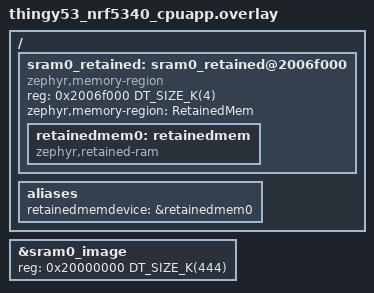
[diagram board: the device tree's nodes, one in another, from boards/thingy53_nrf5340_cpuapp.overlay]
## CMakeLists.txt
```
cmake_minimum_required(VERSION 3.20.0)

find_package(Zephyr REQUIRED HINTS $ENV{ZEPHYR_BASE})
project(fridge_monitor)

target_sources(app PRIVATE
  src/main.cpp
  src/app.cpp
  src/bh1749_light.cpp
)

if(CONFIG_BT)
  target_sources(app PRIVATE
    src/ble_nus.cpp
  )
endif()
```

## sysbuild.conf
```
# Use hci_ipc for BLE on network core instead of empty_net_core.
SB_CONFIG_NETCORE_HCI_IPC=y
```

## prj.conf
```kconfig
# C++
CONFIG_CPP=y
CONFIG_STD_CPP20=y

# I2C for direct BH1749 access (bypassing Zephyr sensor API to avoid SYS_INIT).
CONFIG_I2C=y

# GPIO (for INT)
CONFIG_GPIO=y

# Power management
CONFIG_POWEROFF=y

# nrfx reset reason helper
CONFIG_NRFX_POWER=y

# Retained memory for calibration persistence across System OFF.
CONFIG_RETAINED_MEM=y
CONFIG_CRC=y

# BLE
CONFIG_BT=y
CONFIG_BT_PERIPHERAL=y
CONFIG_BT_DEVICE_NAME="FridgeMon"
CONFIG_BT_NUS=y
# Disable auto connection parameter updates (short-lived connections).
CONFIG_BT_GAP_AUTO_UPDATE_CONN_PARAMS=n

# Logging (RTT)
CONFIG_LOG=y
CONFIG_LOG_DEFAULT_LEVEL=3
CONFIG_USE_SEGGER_RTT=y
CONFIG_LOG_BACKEND_RTT=y
CONFIG_LOG_MODE_IMMEDIATE=y
CONFIG_LOG_BACKEND_UART=n

CONFIG_MAIN_STACK_SIZE=2048
```

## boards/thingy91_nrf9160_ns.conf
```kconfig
# Thingy:91 specific configuration (non-secure build with TF-M).

# Disable TF-M UART logging - it conflicts with I2C (same peripheral base address).
CONFIG_TFM_SECURE_UART=n
CONFIG_TFM_LOG_LEVEL_SILENCE=y

# Thingy:91 uses LTE modem, no BLE.
CONFIG_BT=n
CONFIG_BT_PERIPHERAL=n
CONFIG_BT_NUS=n
```

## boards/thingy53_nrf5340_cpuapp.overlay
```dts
/* BH1749 INT pin is already defined in thingy53_nrf5340_common.dtsi as:
 *   int-gpios = <&gpio1 5 (GPIO_PULL_UP | GPIO_ACTIVE_LOW)>;
 * No overlay needed for that.
 */

/* Retained memory region for calibration persistence across System OFF.
 * Uses the last 4KB of SRAM which remains powered during System OFF.
 */
/ {
  sram0_retained: sram0_retained@2006f000 {
    compatible = "zephyr,memory-region", "mmio-sram";
    reg = <0x2006f000 DT_SIZE_K(4)>;
    zephyr,memory-region = "RetainedMem";
    status = "okay";

    retainedmem0: retainedmem {
      compatible = "zephyr,retained-ram";
      status = "okay";
    };
  };

  aliases {
    retainedmemdevice = &retainedmem0;
  };
};

/* Shrink SRAM to avoid overlap with retained region.
 * Default is 448KB, we reduce to 444KB (448 - 4 = 444).
 */
&sram0_image {
  reg = <0x20000000 DT_SIZE_K(444)>;
};
```

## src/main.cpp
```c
/*
 * Fridge Light Monitor for Thingy:53 (nRF5340)
 *
 * Wakes from System OFF on button press or BH1749 light threshold,
 * monitors door open/close events, transmits data over BLE NUS to gateway,
 * then returns to System OFF.
 */

#include <zephyr/kernel.h>
#include <zephyr/logging/log.h>

#include "app.hpp"

LOG_MODULE_REGISTER(main, LOG_LEVEL_INF);

int main()
{
  LOG_INF("ALC Fridge Light Monitor - Starting.");

  fridge::App app;

  if (!app.Init()) {
    LOG_ERR("Application init failed!");
    return -1;
  }

  app.Run();

  // Run() enters System OFF, so we should never reach here.
  LOG_ERR("Application returned unexpectedly!");
  return -1;
}
```

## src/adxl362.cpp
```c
#include "adxl362.hpp"

#include <zephyr/kernel.h>
#include <zephyr/logging/log.h>

LOG_MODULE_REGISTER(adxl362, LOG_LEVEL_INF);

namespace drawer {

  // ========== SPI Command Bytes ==========

  constexpr uint8_t M_CMD_WRITE_REG  { 0x0A };
  constexpr uint8_t M_CMD_READ_REG   { 0x0B };
  constexpr uint8_t M_CMD_READ_FIFO  { 0x0D };

  // ========== Register Addresses ==========

  constexpr uint8_t M_REG_DEVID_AD        { 0x00 };
  constexpr uint8_t M_REG_DEVID_MST       { 0x01 };
  constexpr uint8_t M_REG_PARTID          { 0x02 };
  constexpr uint8_t M_REG_STATUS          { 0x0B };
  constexpr uint8_t M_REG_FIFO_L          { 0x0C };
  // constexpr uint8_t M_REG_FIFO_H          { 0x0D };
  constexpr uint8_t M_REG_XDATA_L         { 0x0E };
  constexpr uint8_t M_REG_SOFT_RESET      { 0x1F };
  constexpr uint8_t M_REG_THRESH_ACT_L    { 0x20 };
  constexpr uint8_t M_REG_TIME_ACT        { 0x22 };
  constexpr uint8_t M_REG_THRESH_INACT_L  { 0x23 };
  constexpr uint8_t M_REG_TIME_INACT_L    { 0x25 };
  constexpr uint8_t M_REG_ACT_INACT_CTL   { 0x27 };
  constexpr uint8_t M_REG_FIFO_CTL        { 0x28 };
  constexpr uint8_t M_REG_FIFO_SAMPLES    { 0x29 };
  constexpr uint8_t M_REG_INTMAP1         { 0x2A };
  constexpr uint8_t M_REG_FILTER_CTL      { 0x2C };
  constexpr uint8_t M_REG_POWER_CTL       { 0x2D };

  // ========== Bit Masks and Shifts ==========

  // STATUS (0x0B).
  constexpr uint8_t M_STATUS_DATA_READY    { BIT(0) };
  constexpr uint8_t M_STATUS_FIFO_READY    { BIT(1) };
  constexpr uint8_t M_STATUS_FIFO_WM       { BIT(2) };
  constexpr uint8_t M_STATUS_FIFO_OVERRUN  { BIT(3) };
  constexpr uint8_t M_STATUS_ACT           { BIT(4) };
  constexpr uint8_t M_STATUS_INACT         { BIT(5) };
  constexpr uint8_t M_STATUS_AWAKE         { BIT(6) };
  constexpr uint8_t M_STATUS_ERR_USER_REGS { BIT(7) };

  // ACT_INACT_CTL (0x27).
  constexpr uint8_t M_ACT_EN              { BIT(0) };
  // constexpr uint8_t M_ACT_REF             { BIT(1) };
  constexpr uint8_t M_INACT_EN            { BIT(2) };
  // constexpr uint8_t M_INACT_REF           { BIT(3) };
  constexpr uint8_t M_LINKLOOP_SHIFT      { 4 };
  // constexpr uint8_t M_LINKLOOP_MASK       { 0x30 };

  // FIFO_CTL (0x28).
  // constexpr uint8_t M_FIFO_MODE_MASK      { 0x03 };
  // constexpr uint8_t M_FIFO_TEMP           { BIT(2) };
  constexpr uint8_t M_FIFO_AH             { BIT(3) };

  // FILTER_CTL (0x2C).
  constexpr uint8_t M_ODR_MASK            { 0x07 };
  constexpr uint8_t M_RANGE_SHIFT         { 6 };
  constexpr uint8_t M_RANGE_MASK          { 0xC0 };

  // POWER_CTL (0x2D).
  constexpr uint8_t M_MEASURE_MASK        { 0x03 };
  constexpr uint8_t M_MEASURE_ON          { 0x02 };
  constexpr uint8_t M_MEASURE_STANDBY     { 0x00 };
  // constexpr uint8_t M_AUTOSLEEP           { BIT(2) };
  // constexpr uint8_t M_WAKEUP              { BIT(3) };
  // constexpr uint8_t M_LOW_NOISE_SHIFT     { 4 };
  // constexpr uint8_t M_LOW_NOISE_MASK      { 0x30 };
  // constexpr uint8_t M_EXTCLK             { BIT(6) };

  // INTMAP1 (0x2A).
  // constexpr uint8_t M_INTMAP_DATA_READY   { BIT(0) };
  // constexpr uint8_t M_INTMAP_FIFO_READY   { BIT(1) };
  // constexpr uint8_t M_INTMAP_FIFO_WM      { BIT(2) };
  // constexpr uint8_t M_INTMAP_FIFO_OVERRUN { BIT(3) };
  // constexpr uint8_t M_INTMAP_ACT          { BIT(4) };
  // constexpr uint8_t M_INTMAP_INACT        { BIT(5) };
  constexpr uint8_t M_INTMAP_AWAKE        { BIT(6) };
  // constexpr uint8_t M_INTMAP_INT_LOW      { BIT(7) };

  // FIFO data format.
  // constexpr uint16_t M_FIFO_HDR_MASK      { 0xC000 };
  // constexpr uint8_t  M_FIFO_HDR_SHIFT     { 14 };
  constexpr uint16_t M_FIFO_DATA_MASK     { 0x3FFF };
  constexpr uint16_t M_FIFO_SIGN_BIT      { 0x2000 };
  constexpr uint16_t M_FIFO_SIGN_EXTEND   { 0xC000 };

  // Scale factors (mg per LSB).
  constexpr float M_SCALE_2G { 1.0f };     // 1000 LSB/g → 1 mg/LSB.
  constexpr float M_SCALE_4G { 2.0f };     // 500 LSB/g → 2 mg/LSB.
  constexpr float M_SCALE_8G { 4.255f };   // 235 LSB/g → ~4.255 mg/LSB.

  // Threshold scale (mg per LSB, same as data for ±2g default).
  // constexpr float M_THRESH_SCALE_2G { 1.0f };
  // constexpr float M_THRESH_SCALE_4G { 2.0f };
  // constexpr float M_THRESH_SCALE_8G { 4.255f };

  // FIFO entry count mask.
  // constexpr uint16_t M_FIFO_COUNT_MASK { 0x03FF };

  // ========== Constructor ==========

  Adxl362::Adxl362(const struct spi_dt_spec* spiSpec)
      : m_spi(spiSpec)
      , m_currentRange(Range::Range2g)
  {
  }

  // ========== SPI Helpers ==========

  int Adxl362::writeRegister(uint8_t reg, uint8_t value)
  {
    uint8_t txBuf[3] { M_CMD_WRITE_REG, reg, value };
    const struct spi_buf tx { .buf = txBuf, .len = sizeof(txBuf) };
    const struct spi_buf_set txSet { .buffers = &tx, .count = 1 };

    int result { spi_write_dt(m_spi, &txSet) };
    if (result < 0) {
      LOG_ERR("SPI write failed: reg=0x%02X, err=%d!", reg, result);
    }
    return result;
  }

  int Adxl362::readRegister(uint8_t reg, uint8_t& value)
  {
    uint8_t txBuf[2] { M_CMD_READ_REG, reg };
    const struct spi_buf txSpi { .buf = txBuf, .len = sizeof(txBuf) };
    const struct spi_buf_set txSet { .buffers = &txSpi, .count = 1 };

    uint8_t rxBuf[3] { 0 };
    const struct spi_buf rxSpi { .buf = rxBuf, .len = sizeof(rxBuf) };
    const struct spi_buf_set rxSet { .buffers = &rxSpi, .count = 1 };

    int result { spi_transceive_dt(m_spi, &txSet, &rxSet) };
    if (result < 0) {
      LOG_ERR("SPI read failed: reg=0x%02X, err=%d!", reg, result);
      return result;
    }

    // Data appears after 2-byte command in rx buffer.
    value = rxBuf[2];
    return 0;
  }

  int Adxl362::readRegisters(uint8_t reg, uint8_t* buffer, size_t length)
  {
    uint8_t txBuf[2] { M_CMD_READ_REG, reg };
    const struct spi_buf txSpi { .buf = txBuf, .len = sizeof(txBuf) };
    const struct spi_buf_set txSet { .buffers = &txSpi, .count = 1 };

    // RX: 2 dummy bytes (command echo) + data.
    uint8_t rxHeader[2] { 0 };
    struct spi_buf rxBufs[2] {
      { .buf = rxHeader, .len = sizeof(rxHeader) },
      { .buf = buffer,   .len = length },
    };
    const struct spi_buf_set rxSet { .buffers = rxBufs, .count = 2 };

    int result { spi_transceive_dt(m_spi, &txSet, &rxSet) };
    if (result < 0) {
      LOG_ERR("SPI burst read failed: reg=0x%02X, len=%u, err=%d!", reg, length, result);
    }
    return result;
  }

  int Adxl362::writeRegister16(uint8_t regLow, uint16_t value)
  {
    // ADXL362 multi-byte registers are little-endian.
    uint8_t txBuf[4] {
      M_CMD_WRITE_REG,
      regLow,
      static_cast<uint8_t>(value & 0xFF),
      static_cast<uint8_t>((value >> 8) & 0xFF)
    };
    const struct spi_buf tx { .buf = txBuf, .len = sizeof(txBuf) };
    const struct spi_buf_set txSet { .buffers = &tx, .count = 1 };

    int result { spi_write_dt(m_spi, &txSet) };
    if (result < 0) {
      LOG_ERR("SPI write16 failed: reg=0x%02X, err=%d!", regLow, result);
    }
    return result;
  }

  int Adxl362::updateRegister(uint8_t reg, uint8_t value, uint8_t mask)
  {
    uint8_t current { 0 };
    int result { readRegister(reg, current) };
    if (result < 0) { return result; }

    uint8_t updated { static_cast<uint8_t>((current & ~mask) | (value & mask)) };
    return writeRegister(reg, updated);
  }

  int Adxl362::readFifoBurst(uint8_t* buffer, size_t length)
  {
    uint8_t cmd { M_CMD_READ_FIFO };
    const struct spi_buf txSpi { .buf = &cmd, .len = 1 };
    const struct spi_buf_set txSet { .buffers = &txSpi, .count = 1 };

    // RX: 1 dummy byte (command echo) + FIFO data.
    uint8_t rxDummy { 0 };
    struct spi_buf rxBufs[2] {
      { .buf = &rxDummy, .len = 1 },
      { .buf = buffer,   .len = length },
    };
    const struct spi_buf_set rxSet { .buffers = rxBufs, .count = 2 };

    int result { spi_transceive_dt(m_spi, &txSet, &rxSet) };
    if (result < 0) {
      LOG_ERR("FIFO burst read failed: len=%u, err=%d!", length, result);
    }
    return result;
  }

  // ========== Conversion Helpers ==========

  float Adxl362::getScaleMgPerLsb() const
  {
    switch (m_currentRange) {
      case Range::Range2g: return M_SCALE_2G;
      case Range::Range4g: return M_SCALE_4G;
      case Range::Range8g: return M_SCALE_8G;
      default:             return M_SCALE_2G;
    }
  }

  uint16_t Adxl362::mgToLsb(uint16_t mg) const
  {
    float scale { getScaleMgPerLsb() };
    return static_cast<uint16_t>(static_cast<float>(mg) / scale);
  }

  int Adxl362::verifyDeviceId()
  {
    uint8_t adId { 0 };
    uint8_t memsId { 0 };
    uint8_t partId { 0 };

    int result { readRegister(M_REG_DEVID_AD, adId) };
    if (result < 0) { return result; }

    result = readRegister(M_REG_DEVID_MST, memsId);
    if (result < 0) { return result; }

    result = readRegister(M_REG_PARTID, partId);
    if (result < 0) { return result; }

    if (adId != M_DEVID_AD_EXPECTED || memsId != M_DEVID_MST_EXPECTED ||
        partId != M_PARTID_EXPECTED) {
      LOG_ERR("Device ID mismatch: AD=0x%02X MST=0x%02X PART=0x%02X!", adId, memsId, partId);
      return -ENODEV;
    }

    LOG_INF("Device ID verified: AD=0x%02X MST=0x%02X PART=0x%02X.", adId, memsId, partId);
    return 0;
  }

  // ========== Initialisation ==========

  int Adxl362::Init()
  {
    if (!spi_is_ready_dt(m_spi)) {
      LOG_ERR("SPI bus not ready!");
      return -ENODEV;
    }

    // Software reset.
    int result { writeRegister(M_REG_SOFT_RESET, M_SOFT_RESET_CODE) };
    if (result < 0) {
      LOG_ERR("Soft reset failed: %d!", result);
      return result;
    }

    k_msleep(M_RESET_DELAY_MS);

    result = verifyDeviceId();
    if (result < 0) { return result; }

    LOG_INF("ADXL362 initialised.");
    return 0;
  }

  // ========== Configuration ==========

  int Adxl362::ConfigureActivity(const ActivityConfig& config)
  {
    // Activity threshold (11-bit, little-endian across two registers).
    uint16_t actLsb { static_cast<uint16_t>(mgToLsb(config.activityThresholdMg) & 0x07FF) };
    int result { writeRegister16(M_REG_THRESH_ACT_L, actLsb) };
    if (result < 0) { return result; }

    // Activity time.
    result = writeRegister(M_REG_TIME_ACT, config.activityTime);
    if (result < 0) { return result; }

    // Inactivity threshold (11-bit).
    uint16_t inactLsb { static_cast<uint16_t>(mgToLsb(config.inactivityThresholdMg) & 0x07FF) };
    result = writeRegister16(M_REG_THRESH_INACT_L, inactLsb);
    if (result < 0) { return result; }

    // Inactivity time (16-bit).
    result = writeRegister16(M_REG_TIME_INACT_L, config.inactivityTime);
    if (result < 0) { return result; }

    // ACT_INACT_CTL: enable bits, reference mode, link/loop.
    uint8_t ctlValue { static_cast<uint8_t>(
        M_ACT_EN |
        (static_cast<uint8_t>(config.activityMode) << 1) |
        M_INACT_EN |
        (static_cast<uint8_t>(config.inactivityMode) << 3) |
        (static_cast<uint8_t>(config.linkLoop) << M_LINKLOOP_SHIFT)
    )};

    result = writeRegister(M_REG_ACT_INACT_CTL, ctlValue);
    if (result < 0) { return result; }

    LOG_INF("Activity configured: act=%umg/%u, inact=%umg/%u, loop=%u.",
            config.activityThresholdMg, config.activityTime,
            config.inactivityThresholdMg, config.inactivityTime,
            static_cast<uint8_t>(config.linkLoop));
    return 0;
  }

  int Adxl362::ConfigureFifo(FifoMode mode, uint16_t watermark)
  {
    uint8_t fifoCtl { static_cast<uint8_t>(mode) };
    if (watermark & 0x100) {
      fifoCtl |= M_FIFO_AH;
    }

    int result { writeRegister(M_REG_FIFO_CTL, fifoCtl) };
    if (result < 0) { return result; }

    result = writeRegister(M_REG_FIFO_SAMPLES, static_cast<uint8_t>(watermark & 0xFF));
    if (result < 0) { return result; }

    LOG_INF("FIFO configured: mode=%u, watermark=%u.", static_cast<uint8_t>(mode), watermark);
    return 0;
  }

  int Adxl362::SetOdr(ODR odr)
  {
    int result { updateRegister(M_REG_FILTER_CTL, static_cast<uint8_t>(odr), M_ODR_MASK) };
    if (result < 0) {
      LOG_ERR("Failed to set ODR: %d!", result);
      return result;
    }

    LOG_INF("ODR set to %u.", static_cast<uint8_t>(odr));
    return 0;
  }

  int Adxl362::SetRange(Range range)
  {
    uint8_t value { static_cast<uint8_t>(static_cast<uint8_t>(range) << M_RANGE_SHIFT) };
    int result { updateRegister(M_REG_FILTER_CTL, value, M_RANGE_MASK) };
    if (result < 0) {
      LOG_ERR("Failed to set range: %d!", result);
      return result;
    }

    m_currentRange = range;

    const char* rangeStr[] { "±2g", "±4g", "±8g" };
    LOG_INF("Range set to %s.", rangeStr[static_cast<uint8_t>(range)]);
    return 0;
  }

  int Adxl362::StartMeasurement()
  {
    int result { updateRegister(M_REG_POWER_CTL, M_MEASURE_ON, M_MEASURE_MASK) };
    if (result < 0) {
      LOG_ERR("Failed to start measurement: %d!", result);
      return result;
    }

    LOG_INF("Measurement mode started.");
    return 0;
  }

  int Adxl362::StopMeasurement()
  {
    int result { updateRegister(M_REG_POWER_CTL, M_MEASURE_STANDBY, M_MEASURE_MASK) };
    if (result < 0) {
      LOG_ERR("Failed to stop measurement: %d!", result);
      return result;
    }

    LOG_INF("Standby mode entered.");
    return 0;
  }

  // ========== FIFO ==========

  int Adxl362::ReadFifoEntries(uint16_t& entries)
  {
    uint8_t buf[2] { 0 };
    int result { readRegisters(M_REG_FIFO_L, buf, 2) };
    if (result < 0) { return result; }

    entries = static_cast<uint16_t>(buf[0] | ((buf[1] & 0x03) << 8));
    return 0;
  }

  int Adxl362::ReadFifo(Sample* samples, uint16_t maxSets, uint16_t& setsRead)
  {
    constexpr int OK { 0 };
    constexpr size_t TOTAL_AXES { 3 };
    constexpr size_t BYTES_PER_AXIS { 2 } ;
    constexpr size_t TOTAL_SETS { 512 };
    constexpr size_t BYTES_PER_SET { TOTAL_AXES * BYTES_PER_AXIS };

    setsRead = 0;

    // Read FIFO entry count.
    uint16_t entries { 0 };
    int result { ReadFifoEntries(entries) };
    if (result < 0) { return result; }

    LOG_INF("FIFO entries: %u.", entries);
    if (entries == 0) { return 0; }

    // Each XYZ set = 3 entries of 2 bytes each.
    uint16_t availableSets { static_cast<uint16_t>(entries / TOTAL_AXES) };
    uint16_t setsToRead { (availableSets > maxSets) ? maxSets : availableSets };
    uint16_t bytesToRead { static_cast<uint16_t>(setsToRead * BYTES_PER_SET) };

    if (bytesToRead == 0) { return 0; }

    // Read raw FIFO data.
    uint8_t raw[TOTAL_SETS * BYTES_PER_SET];  // 3072.
    if (bytesToRead > sizeof(raw)) {
      setsToRead = sizeof(raw) / BYTES_PER_SET;
      bytesToRead = static_cast<uint16_t>(setsToRead * BYTES_PER_SET);
    }

    result = readFifoBurst(raw, bytesToRead);
    if (result < 0) {
      LOG_ERR("FIFO burst read failed: %d!", result);
      return result;
    }

    // Decode samples from FIFO format.
    // Each entry: bits[15:14] = channel ID, bits[13:0] = signed 14-bit data.
    float scale { getScaleMgPerLsb() };

    for (uint16_t i { 0 }; i < setsToRead; ++i) 
    {
      for (uint8_t axis { 0 }; axis < TOTAL_AXES; ++axis) 
      {
        uint16_t offset { static_cast<uint16_t>((i * TOTAL_AXES + axis) * BYTES_PER_AXIS) };
        uint16_t raw16 { static_cast<uint16_t>(raw[offset] | (raw[offset + 1] << 8)) };

        // Extract 14-bit signed value.
        int16_t rawVal { static_cast<int16_t>(raw16 & M_FIFO_DATA_MASK) };
        if (rawVal & M_FIFO_SIGN_BIT) {
          rawVal |= static_cast<int16_t>(M_FIFO_SIGN_EXTEND);
        }

        int16_t mg { static_cast<int16_t>(static_cast<float>(rawVal) * scale) };

        switch (axis) {
          case 0: samples[i].x = mg; break;
          case 1: samples[i].y = mg; break;
          case 2: samples[i].z = mg; break;
        }
      }
    }

    setsRead = setsToRead;
    LOG_INF("Read %u sample sets from FIFO.", setsRead);

    return OK;
  }

  // ========== Status ==========

  int Adxl362::ReadStatus(Status& status)
  {
    constexpr int OK { 0 };
    uint8_t value { 0 };
    int result { readRegister(M_REG_STATUS, value) };
    if (result < 0) {
      LOG_ERR("Failed to read status: %d!", result);
      return result;
    }

    status.dataReady     = (value & M_STATUS_DATA_READY) != 0;
    status.fifoReady     = (value & M_STATUS_FIFO_READY) != 0;
    status.fifoWatermark = (value & M_STATUS_FIFO_WM) != 0;
    status.fifoOverrun   = (value & M_STATUS_FIFO_OVERRUN) != 0;
    status.activity      = (value & M_STATUS_ACT) != 0;
    status.inactivity    = (value & M_STATUS_INACT) != 0;
    status.awake         = (value & M_STATUS_AWAKE) != 0;
    status.errUserRegs   = (value & M_STATUS_ERR_USER_REGS) != 0;

    return OK;
  }

  bool Adxl362::IsAwake()
  {
    Status status;
    if (ReadStatus(status) < 0) {
      return true;  // Default to awake on error (safer).
    }
    return status.awake;
  }

  // ========== Interrupt Mapping ==========

  int Adxl362::MapAwakeToInt1()
  {
    constexpr int OK { 0 };
    int result { writeRegister(M_REG_INTMAP1, M_INTMAP_AWAKE) };
    if (result < 0) {
      LOG_ERR("Failed to map AWAKE to INT1: %d!", result);
      return result;
    }

    LOG_INF("AWAKE mapped to INT1.");

    return OK;
  }

  // ========== Data Register Reads ==========

  int Adxl362::ReadAxes(int16_t& x, int16_t& y, int16_t& z)
  {
    constexpr int OK { 0 };
    // Burst read 6 bytes: XDATA_L, XDATA_H, YDATA_L, YDATA_H, ZDATA_L, ZDATA_H.
    uint8_t raw[6];
    int result { readRegisters(M_REG_XDATA_L, raw, 6) };
    if (result < 0) {
      LOG_ERR("Failed to read axes: %d!", result);
      return result;
    }

    float scale { getScaleMgPerLsb() };

    // Data registers are 12-bit, little-endian, right-justified.
    auto decode = [scale](uint8_t lo, uint8_t hi) -> int16_t {
      int16_t rawVal { static_cast<int16_t>((hi << 8) | lo) };
      return static_cast<int16_t>(static_cast<float>(rawVal) * scale);
    };

    x = decode(raw[0], raw[1]);
    y = decode(raw[2], raw[3]);
    z = decode(raw[4], raw[5]);

    return OK;
  }
}
```

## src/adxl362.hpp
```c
#pragma once

/**
 * @file adxl362.hpp
 * @brief ADXL362 accelerometer driver — Zephyr-free class using direct SPI register access.
 *
 * Provides activity/inactivity detection (loop mode), FIFO streaming, and AWAKE→INT1
 * mapping for System OFF wake. Uses SPI via Zephyr's spi_dt_spec only for bus access;
 * all register configuration is handled directly (no Zephyr sensor API at runtime).
 */

#include <zephyr/device.h>
#include <zephyr/drivers/spi.h>

namespace drawer 
{
  class Adxl362
  {
    public:
      // ========== Enumerations ==========

      enum class Range : uint8_t {
        Range2g = 0x00,   ///< ±2g (1000 LSB/g).
        Range4g = 0x01,   ///< ±4g (500 LSB/g).
        Range8g = 0x02    ///< ±8g (235 LSB/g).
      };

      enum class ODR : uint8_t {
        Odr12_5  = 0x00,  ///< 12.5 Hz.
        Odr25    = 0x01,  ///< 25 Hz.
        Odr50    = 0x02,  ///< 50 Hz.
        Odr100   = 0x03,  ///< 100 Hz.
        Odr200   = 0x04,  ///< 200 Hz.
        Odr400   = 0x05   ///< 400 Hz.
      };

      enum class FifoMode : uint8_t {
        Disabled     = 0x00,
        OldestSaved  = 0x01,
        Stream       = 0x02,
        Triggered    = 0x03
      };

      enum class LinkLoopMode : uint8_t {
        Default = 0x00,   ///< Default (independent act/inact).
        Linked  = 0x01,   ///< Linked mode.
        Loop    = 0x03    ///< Loop mode (auto-acknowledged).
      };

      enum class ActivityMode : uint8_t {
        Absolute   = 0x00,
        Referenced = 0x01
      };

      // ========== Structures ==========

      /** @brief Decoded status register contents. */
      struct Status {
        bool dataReady;       ///< New data available.
        bool fifoReady;       ///< FIFO has at least one sample.
        bool fifoWatermark;   ///< FIFO watermark reached.
        bool fifoOverrun;     ///< FIFO overrun.
        bool activity;        ///< Activity detected.
        bool inactivity;      ///< Inactivity detected.
        bool awake;           ///< Device is in awake state.
        bool errUserRegs;     ///< SEU error detected in user registers.
      };

      /** @brief Single XYZ acceleration sample in mg. */
      struct Sample {
        int16_t x;
        int16_t y;
        int16_t z;
      };

      /** @brief Activity/inactivity detection configuration. */
      struct ActivityConfig {
        ActivityMode activityMode;
        ActivityMode inactivityMode;
        LinkLoopMode linkLoop;
        uint16_t activityThresholdMg;     ///< Activity threshold in mg.
        uint8_t  activityTime;            ///< Activity time in samples.
        uint16_t inactivityThresholdMg;   ///< Inactivity threshold in mg.
        uint16_t inactivityTime;          ///< Inactivity time in samples.
      };

      /** @brief Default config for drawer motion detection. */
      static constexpr ActivityConfig DEFAULT_DRAWER_CONFIG {
        .activityMode         = ActivityMode::Referenced,
        .inactivityMode       = ActivityMode::Referenced,
        .linkLoop             = LinkLoopMode::Loop,
        .activityThresholdMg  = 120,
        .activityTime         = 1,
        .inactivityThresholdMg = 150,
        .inactivityTime       = 200    // 2s at 100 Hz.
      };

      // ========== Constructor ==========

      /**
       * @brief Construct an ADXL362 driver instance.
       * @param spiSpec Pointer to a Zephyr spi_dt_spec (from devicetree).
       */
      explicit Adxl362(const struct spi_dt_spec* spiSpec);

      // ========== Initialisation ==========

      /** @brief Reset device, verify ID, and apply default configuration. */
      int Init();

      // ========== Configuration ==========

      /** @brief Configure activity/inactivity detection and link/loop mode. */
      int ConfigureActivity(const ActivityConfig& config);

      /** @brief Configure FIFO mode and watermark. */
      int ConfigureFifo(FifoMode mode, uint16_t watermark);

      /** @brief Set output data rate. */
      int SetOdr(ODR odr);

      /** @brief Set measurement range. */
      int SetRange(Range range);

      /** @brief Enter measurement mode. */
      int StartMeasurement();

      /** @brief Return to standby. */
      int StopMeasurement();

      // ========== FIFO ==========

      /** @brief Read FIFO entry count (number of 16-bit words). */
      int ReadFifoEntries(uint16_t& entries);

      /**
       * @brief Read complete XYZ sample sets from FIFO.
       * @param samples Output buffer for decoded samples.
       * @param maxSets Maximum number of XYZ sets to read.
       * @param setsRead Actual number of sets read.
       */
      int ReadFifo(Sample* samples, uint16_t maxSets, uint16_t& setsRead);

      // ========== Status ==========

      /** @brief Read and decode the status register. */
      int ReadStatus(Status& status);

      /** @brief Check if device is in awake state. */
      bool IsAwake();

      // ========== Interrupt Mapping ==========

      /** @brief Map AWAKE signal to INT1 for System OFF wake. */
      int MapAwakeToInt1();

      // ========== Data Register Reads ==========

      /** @brief Read XYZ from data registers (not FIFO). */
      int ReadAxes(int16_t& x, int16_t& y, int16_t& z);

    private:
      // ========== SPI Helpers ==========

      int writeRegister(uint8_t reg, uint8_t value);
      int readRegister(uint8_t reg, uint8_t& value);
      int readRegisters(uint8_t reg, uint8_t* buffer, size_t length);
      int writeRegister16(uint8_t regLow, uint16_t value);
      int updateRegister(uint8_t reg, uint8_t value, uint8_t mask);
      int readFifoBurst(uint8_t* buffer, size_t length);

      // ========== Conversion Helpers ==========

      uint16_t mgToLsb(uint16_t mg) const;
      float getScaleMgPerLsb() const;
      int verifyDeviceId();

      // ========== Member Variables ==========

      const struct spi_dt_spec* m_spi;
      Range m_currentRange;

      // ========== Constants ==========

      static constexpr uint8_t M_RESET_DELAY_MS    { 5 };
      static constexpr uint8_t M_SOFT_RESET_CODE   { 0x52 };
      static constexpr uint8_t M_DEVID_AD_EXPECTED  { 0xAD };
      static constexpr uint8_t M_DEVID_MST_EXPECTED { 0x1D };
      static constexpr uint8_t M_PARTID_EXPECTED    { 0xF2 };
  };
} 
```

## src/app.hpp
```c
#pragma once

/**
 * @file app.hpp
 * @brief ALC Fridge Light Monitor Application State Machine.
 *
 * Manages the device lifecycle from activation through normal operation:
 *
 * States:
 * - PowerOff:    Deep sleep (System OFF), waiting for button or light wake.
 * - Activating:  User pressed button, searching for gateway, calibrating.
 * - NoCentral:   Gateway not found during activation.
 * - Standby:     Activation failed or uncalibrated, waiting for button retry.
 * - Ready:       Activated and calibrated, waiting for light wake.
 * - Monitoring:  Light detected (door open), monitoring for close.
 *
 * Button (sw0 / SW2 on Thingy:53 silkscreen, P1.14):
 * - Short press from PowerOff/Standby: Start activation.
 * - Long press (3s) from any state: Power off.
 * - Very long press (10s): Factory reset (clear calibration).
 *
 * Light sensor (BH1749 INT on P1.05):
 * - Wake from System OFF when light exceeds calibrated threshold.
 * - Send OPEN event, monitor for door close, send CLOSE event with duration.
 * - Alert if door open > timeout.
 */

#include <cstdint>

namespace fridge
{
  // ========== Application States ==========

  enum class AppState : uint8_t {
    PowerOff,       // System OFF, waiting for wake.
    Activating,     // Button pressed, finding gateway + calibrating.
    NoCentral,      // Gateway not found.
    Standby,        // Failed activation, waiting for retry.
    Ready,          // Activated, waiting for light wake.
    Monitoring      // Door open, monitoring for close.
  };

  // ========== Wake Source Identification ==========

  enum class WakeSource : uint8_t {
    PowerOn,        // Fresh boot (power-on reset, debug reset, etc.).
    Button,         // User pressed button (sw0).
    LightInterrupt  // BH1749 light threshold exceeded (door opened).
  };

  // ========== Calibration Data ==========

  struct CalibrationData {
    uint16_t wakeThreshold;     // Light level to trigger wake (green channel).
    uint16_t doorOpenLight;     // Measured door-open light level (green channel).
    uint16_t doorClosedLight;   // Measured door-closed light level (green channel).
    int8_t txPowerDbm;          // Calibrated TX power.
    uint8_t valid;              // Magic number to detect uninitialised.
  };

  // Magic value indicating valid calibration.
  constexpr uint8_t M_CALIBRATION_VALID_MAGIC { 0xCA };

  // ========== Timing Constants ==========

  constexpr uint32_t M_BUTTON_LONG_PRESS_MS { 3000 };      // Power off threshold.
  constexpr uint32_t M_BUTTON_FACTORY_RESET_MS { 10000 };  // Factory reset threshold.
  constexpr uint32_t M_ACTIVATION_TIMEOUT_MS { 30000 };    // Gateway search timeout.
  constexpr uint32_t M_CALIBRATION_TIMEOUT_MS { 300000 };  // 5 minutes for door close.
  constexpr uint32_t M_POLL_INTERVAL_MS { 500 };           // Calibration poll interval.

  // ========== Calibration Constants ==========

  constexpr uint8_t M_SAMPLES_PER_READING { 5 };           // Samples averaged per reading.
  constexpr uint8_t M_DOOR_CLOSE_CONSECUTIVE { 3 };        // Consecutive low readings to confirm closed.
  constexpr uint8_t M_DOOR_CLOSE_THRESHOLD_PERCENT { 30 }; // % of open level to detect closed.
  constexpr uint8_t M_VALID_CALIBRATION_PERCENT { 50 };    // Max closed/open ratio for valid cal.
  constexpr uint8_t M_WAKE_THRESHOLD_OFFSET_PERCENT { 30 };// Wake threshold: closed + 30% of range.

  // ========== Application Class ==========

  class App
  {
    public:
      App();

      /**
       * @brief Initialise application hardware.
       * @return true on success.
       */
      bool Init();

      /**
       * @brief Run the application state machine.
       *
       * Handles the current wake event and transitions to appropriate state.
       * May enter System OFF at the end.
       */
      void Run();

      /**
       * @brief Get the wake source that caused this boot.
       * @return The detected wake source.
       */
      WakeSource GetWakeSource() const { return m_wakeSource; }

      /**
       * @brief Get the current application state.
       * @return The current state.
       */
      AppState GetState() const { return m_state; }

    private:
      // ========== State Handlers ==========

      void handlePowerOnWake();
      void handleButtonWake();
      void handleLightInterruptWake();

      // ========== Button Handling ==========

      bool checkFactoryReset();

      // ========== Activation Sequence ==========

      bool runActivationSequence();
      bool findGateway();
      bool calibrateLightSensor();

      // ========== Normal Operation ==========

      void sendDoorOpenAndSleep();
      bool sendOpenEvent(int8_t rssi, int8_t txPower);

      // ========== Calibration Events ==========

      bool sendCalibrationEvent(uint8_t status, int8_t rssi);

      // ========== Hardware Configuration ==========

      bool initLightSensor();
      void configureLightSensorForWake();
      void configureLightSensorForDoorClose();

      // ========== Wake Source Detection ==========

      WakeSource detectWakeSource();

      // ========== LED Feedback ==========

      void ledSetAmber();
      void ledSetRed();
      void ledSetGreen();
      void ledOff();
      void ledBlink(int count, int onMs, int offMs);
      void ledPulseAmber();
      void ledStopPulse();

      // ========== Power Management ==========

      void configureWakeSources();
      void enterSystemOff();

      // ========== State Management ==========

      void setState(AppState newState);

      // ========== Calibration Persistence ==========

      bool loadCalibration();
      void saveCalibration();
      void saveRetainedData();
      void clearCalibration();
      bool isCalibrated() const;

      // ========== Helper Functions ==========

      uint16_t calculateWakeThreshold(uint16_t doorOpenLight, uint16_t doorClosedLight);
      uint16_t sampleLightLevel();  // Takes M_SAMPLES_PER_READING samples and averages.

      // ========== Member Variables ==========

      AppState m_state;
      WakeSource m_wakeSource;
      CalibrationData m_calibration;
      uint16_t m_doorOpenLight;      // Light level when door opened (this wake cycle).
  };

  // ========== Free Functions ==========

  const char* appStateToString(AppState state);
  const char* wakeSourceToString(WakeSource source);

} // namespace fridge
```

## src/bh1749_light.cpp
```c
#include <zephyr/kernel.h>
#include <zephyr/drivers/i2c.h>
#include <zephyr/logging/log.h>

#include "bh1749_light.hpp"

LOG_MODULE_REGISTER(bh1749_light, LOG_LEVEL_INF);

namespace fridge 
{
  // ========== Register Addresses ==========

  constexpr uint8_t M_REG_SYSTEM_CONTROL   { 0x40 };
  constexpr uint8_t M_REG_MODE_CONTROL1    { 0x41 };
  constexpr uint8_t M_REG_MODE_CONTROL2    { 0x42 };
  constexpr uint8_t M_REG_RED_DATA_LSB     { 0x50 };
  constexpr uint8_t M_REG_MANUFACTURER_ID  { 0x92 };

  // Interrupt registers.
  constexpr uint8_t M_REG_INTERRUPT        { 0x60 };
  constexpr uint8_t M_REG_PERSISTENCE      { 0x61 };
  constexpr uint8_t M_REG_TH_HIGH_LSB      { 0x62 };
  constexpr uint8_t M_REG_TH_HIGH_MSB      { 0x63 };
  constexpr uint8_t M_REG_TH_LOW_LSB       { 0x64 };
  constexpr uint8_t M_REG_TH_LOW_MSB       { 0x65 };

  // ========== Register Values ==========

  // SYSTEM_CONTROL.
  constexpr uint8_t M_PART_ID_MASK    { 0x3F };
  constexpr uint8_t M_PART_ID         { 0x0D };
  constexpr uint8_t M_SW_RESET        { 0x80 };

  // MODE_CONTROL1.
  constexpr uint8_t M_MEAS_MODE_35MS  { 0x05 };
  constexpr uint8_t M_MEAS_MODE_120MS { 0x02 };
  constexpr uint8_t M_RGB_GAIN_1X     { 0x01 << 3 };
  constexpr uint8_t M_RGB_GAIN_32X    { 0x03 << 3 };
  constexpr uint8_t M_IR_GAIN_1X      { 0x01 << 5 };
  constexpr uint8_t M_IR_GAIN_32X     { 0x03 << 5 };

  // MODE_CONTROL2.
  constexpr uint8_t M_RGB_EN          { 0x10 };
  constexpr uint8_t M_VALID_MASK      { 0x80 };

  // INTERRUPT register bits.
  constexpr uint8_t M_INT_ENABLE       { 0x01 };
  constexpr uint8_t M_INT_SOURCE_RED   { 0x00 << 2 };  // Red channel as interrupt source.
  constexpr uint8_t M_INT_SOURCE_GREEN { 0x01 << 2 };  // Green channel as interrupt source.
  constexpr uint8_t M_INT_SOURCE_BLUE  { 0x02 << 2 };  // Blue channel as interrupt source.
  constexpr uint8_t M_INT_LATCH_YES    { 0x00 << 4 };  // Latched interrupt mode.
  constexpr uint8_t M_INT_LATCH_NO     { 0x01 << 4 };  // Non-latched interrupt mode.

  // PERSISTENCE register values.
  constexpr uint8_t M_PERSISTENCE_ACTIVE_END { 0x00 };  // After each measurement.
  constexpr uint8_t M_PERSISTENCE_UPDATE_END { 0x01 };  // Update measurement end.
  constexpr uint8_t M_PERSISTENCE_4_SAMPLES  { 0x02 };  // 4 consecutive samples.
  constexpr uint8_t M_PERSISTENCE_8_SAMPLES  { 0x03 };  // 8 consecutive samples.

  // MANUFACTURER_ID.
  constexpr uint8_t M_MANUFACTURER_ID { 0xE0 };

  // ========== Constructor ==========

  Bh1749Light::Bh1749Light(const struct i2c_dt_spec* i2cSpec)
      : m_i2c(i2cSpec)
  {
  }

  // ========== Private Methods ==========

  int Bh1749Light::readRegister(uint8_t reg, uint8_t& value)
  {
    return i2c_reg_read_byte_dt(m_i2c, reg, &value);
  }

  int Bh1749Light::writeRegister(uint8_t reg, uint8_t value)
  {
    return i2c_reg_write_byte_dt(m_i2c, reg, value);
  }

  int Bh1749Light::readRegisters(uint8_t startReg, uint8_t* buffer, size_t length)
  {
    return i2c_burst_read_dt(m_i2c, startReg, buffer, length);
  }

  int Bh1749Light::writeRegisters(uint8_t startReg, const uint8_t* buffer, size_t length)
  {
    return i2c_burst_write_dt(m_i2c, startReg, buffer, length);
  }

  // ========== Public Methods ==========

  int Bh1749Light::Init()
  {
    if (!device_is_ready(m_i2c->bus)) {
      LOG_ERR("I2C bus not ready!");
      return -ENODEV;
    }

    // Software reset to ensure clean state.
    int result { writeRegister(M_REG_SYSTEM_CONTROL, M_SW_RESET) };
    if (result < 0) {
      LOG_ERR("Failed to reset BH1749: %d!", result);
      return result;
    }

    // Wait for reset to complete.
    k_msleep(10);

    // Verify manufacturer ID.
    uint8_t mfgId;
    result = readRegister(M_REG_MANUFACTURER_ID, mfgId);
    if (result < 0) {
      LOG_ERR("Failed to read manufacturer ID: %d!", result);
      return result;
    }

    if (mfgId != M_MANUFACTURER_ID) {
      LOG_ERR("Wrong manufacturer ID: 0x%02X (expected 0x%02X)!", mfgId, M_MANUFACTURER_ID);
      return -ENODEV;
    }

    // Verify part ID.
    uint8_t sysCtrl { };
    result = readRegister(M_REG_SYSTEM_CONTROL, sysCtrl);
    if (result < 0) {
      LOG_ERR("Failed to read system control: %d!", result);
      return result;
    }

    uint8_t partId { static_cast<uint8_t>(sysCtrl & M_PART_ID_MASK) };
    if (partId != M_PART_ID) {
      LOG_ERR("Wrong part ID: 0x%02X (expected 0x%02X)!", partId, M_PART_ID);
      return -ENODEV;
    }

    // Set configuration: 32x gain, 120ms mode.
    // Must write MODE_CONTROL1 before enabling measurement in MODE_CONTROL2.
    // 0x02 = 120ms, 0x18 = RGB 32x (bits 4:3 = 11), 0x60 = IR 32x (bits 6:5 = 11)
    constexpr uint8_t MODE_CONTROL1_32X { 0x02 | 0x18 | 0x60 };  // = 0x7A
    result = writeRegister(M_REG_MODE_CONTROL1, MODE_CONTROL1_32X);
    if (result < 0) {
      LOG_ERR("Failed to set mode control 1: %d!", result);
      return result;
    }

    // Enable RGB measurement after setting gain/timing.
    result = writeRegister(M_REG_MODE_CONTROL2, M_RGB_EN);
    if (result < 0) {
      LOG_ERR("Failed to enable RGB: %d!", result);
      return result;
    }

    // Verify gain was set correctly.
    uint8_t modeCtrl1Readback;
    result = readRegister(M_REG_MODE_CONTROL1, modeCtrl1Readback);
    if (result == 0) {
      LOG_INF("MODE_CONTROL1: 0x%02X (expected 0x7A).", modeCtrl1Readback);
    }

    // Clear any pending interrupt from power-on.
    // The BH1749 thresholds default to 0x0000, so any measured value will trigger
    // the interrupt immediately. Reading register 0x60 clears the latch.
    uint8_t intStatus;
    result = readRegister(M_REG_INTERRUPT, intStatus);
    if (result < 0) {
      LOG_WRN("Failed to read/clear interrupt register: %d.", result);
      // Non-fatal, continue.
    } else {
      LOG_INF("Initial INT register: 0x%02X (cleared by reading).", intStatus);
    }

    // Set safe default thresholds to prevent immediate interrupt assertion.
    // High threshold = 0xFFFF (max), Low threshold = 0x0000 (min).
    // This means: interrupt only if value > 65535 (impossible) or < 0 (impossible).
    uint8_t safeThresholds[4] {
      0xFF, 0xFF,  // High threshold LSB, MSB = 0xFFFF.
      0x00, 0x00   // Low threshold LSB, MSB = 0x0000.
    };
    result = writeRegisters(M_REG_TH_HIGH_LSB, safeThresholds, 4);
    if (result < 0) {
      LOG_WRN("Failed to set safe thresholds: %d.", result);
      // Non-fatal, continue.
    } else {
      LOG_INF("Safe thresholds set (high=0xFFFF, low=0x0000).");
    }

    m_ready = true;
    LOG_INF("BH1749 initialised (mfg=0x%02X, part=0x%02X).", mfgId, partId);
    return 0;
  }

  int Bh1749Light::SetGain(Bh1749Gain rgbGain, Bh1749Gain irGain)
  {
    if (!m_ready) { return -ENODEV; }

    uint8_t regVal { M_MEAS_MODE_120MS };
    regVal |= (rgbGain == Bh1749Gain::Gain32x) ? M_RGB_GAIN_32X : M_RGB_GAIN_1X;
    regVal |= (irGain == Bh1749Gain::Gain32x) ? M_IR_GAIN_32X : M_IR_GAIN_1X;

    int result { writeRegister(M_REG_MODE_CONTROL1, regVal) };
    if (result < 0) {
      LOG_ERR("Failed to set gain: %d!", result);
      return result;
    }

    // Clear any stale VALID flag by reading the data registers.
    // This ensures the next Read() waits for fresh data.
    uint8_t dummy[10];
    readRegisters(M_REG_RED_DATA_LSB, dummy, sizeof(dummy));

    LOG_INF("BH1749 gain set: RGB=%s, IR=%s.",
            (rgbGain == Bh1749Gain::Gain32x) ? "32x" : "1x",
            (irGain == Bh1749Gain::Gain32x) ? "32x" : "1x");

    return 0;
  }

  int Bh1749Light::Read(LightReading& reading)
  {
    constexpr int OK { 0 };

    if (!m_ready) { return -ENODEV; }

    // Read all color data (R, G, B, skip 2 bytes, IR) = 10 bytes from 0x50.
    // Layout: RED_L, RED_H, GREEN_L, GREEN_H, BLUE_L, BLUE_H, (2 reserved), IR_L, IR_H.
    // Note: Caller should use WaitForValid() before calling this if fresh data is needed.
    uint8_t buffer[10] { };
    int result { readRegisters(M_REG_RED_DATA_LSB, buffer, sizeof(buffer)) };
    if (result < 0) {
      LOG_ERR("Failed to read color data: %d!", result);
      return result;
    }

    reading.red   = static_cast<uint16_t>(buffer[0] | (buffer[1] << 8));
    reading.green = static_cast<uint16_t>(buffer[2] | (buffer[3] << 8));
    reading.blue  = static_cast<uint16_t>(buffer[4] | (buffer[5] << 8));
    reading.ir    = static_cast<uint16_t>(buffer[8] | (buffer[9] << 8));

    // Store green for threshold checks.
    m_lastGreen = reading.green;

    return OK;
  }

  int Bh1749Light::ConfigureInterrupt(uint16_t thresholdHigh, uint16_t thresholdLow)
  {
    constexpr int OK { 0 };

    if (!m_ready) { return -ENODEV; }

    // Write high threshold (little-endian).
    uint8_t thHighBuf[2] {
      static_cast<uint8_t>(thresholdHigh & 0xFF),
      static_cast<uint8_t>((thresholdHigh >> 8) & 0xFF)
    };
    int result { writeRegisters(M_REG_TH_HIGH_LSB, thHighBuf, 2) };
    if (result < 0) {
      LOG_ERR("Failed to set high threshold: %d!", result);
      return result;
    }

    // Write low threshold (little-endian).
    uint8_t thLowBuf[2] {
      static_cast<uint8_t>(thresholdLow & 0xFF),
      static_cast<uint8_t>((thresholdLow >> 8) & 0xFF)
    };
    result = writeRegisters(M_REG_TH_LOW_LSB, thLowBuf, 2);
    if (result < 0) {
      LOG_ERR("Failed to set low threshold: %d!", result);
      return result;
    }

    // Set persistence to 4 consecutive samples to filter transient changes.
    result = writeRegister(M_REG_PERSISTENCE, M_PERSISTENCE_4_SAMPLES);
    if (result < 0) {
      LOG_ERR("Failed to set persistence: %d!", result);
      return result;
    }

    // Read back to verify.
    constexpr size_t VERIFY_LENGTH { 4 };
    uint8_t verifyBuffer[VERIFY_LENGTH];
    readRegisters(M_REG_TH_HIGH_LSB, verifyBuffer, VERIFY_LENGTH);
    uint16_t readHigh { static_cast<uint16_t>(verifyBuffer[0] | (verifyBuffer[1] << 8)) };
    uint16_t readLow { static_cast<uint16_t>(verifyBuffer[2] | (verifyBuffer[3] << 8)) };

    LOG_INF("BH1749 thresholds: high=%u (read=%u), low=%u (read=%u), persist=4.",
            thresholdHigh, readHigh, thresholdLow, readLow);

    return OK;
  }

  int Bh1749Light::EnableInterrupt(bool enable)
  {
    constexpr int OK { 0 };

    if (!m_ready) { return -ENODEV; }

    // Configure interrupt: green channel source, latched mode.
    // Latched mode keeps INT asserted until cleared by reading register 0x60.
    uint8_t intVal { 0 };
    if (enable) {
      intVal = M_INT_ENABLE | M_INT_SOURCE_GREEN | M_INT_LATCH_YES;
    }

    int result { writeRegister(M_REG_INTERRUPT, intVal) };
    if (result < 0) {
      LOG_ERR("Failed to %s interrupt: %d!", enable ? "enable" : "disable", result);
      return result;
    }

    LOG_INF("BH1749 interrupt %s.", enable ? "enabled" : "disabled");

    return OK;
  }

  int Bh1749Light::ClearInterrupt()
  {
    constexpr int OK { 0 };

    if (!m_ready) { return -ENODEV; }

    // Clear interrupt by READING register 0x60 (INTERRUPT).
    uint8_t intStatus;
    int result { readRegister(M_REG_INTERRUPT, intStatus) };
    if (result < 0) {
      LOG_ERR("Failed to clear interrupt: %d!", result);
      return result;
    }

    LOG_INF("BH1749 interrupt cleared (reg 0x60 was 0x%02X).", intStatus);

    return OK;
  }

  bool Bh1749Light::IsLightAboveThreshold(uint16_t threshold)
  {
    return m_lastGreen >= threshold;
  }

  int Bh1749Light::DumpInterruptRegisters()
  {
    constexpr int OK { 0 };

    if (!m_ready) { return -ENODEV; }

    // Read INTERRUPT register (0x60).
    uint8_t intReg;
    int result { readRegister(M_REG_INTERRUPT, intReg) };
    if (result < 0) {
      LOG_ERR("Failed to read INTERRUPT (0x60): %d!", result);
      return result;
    }

    // Read PERSISTENCE register (0x61).
    uint8_t persReg;
    result = readRegister(M_REG_PERSISTENCE, persReg);
    if (result < 0) {
      LOG_ERR("Failed to read PERSISTENCE (0x61): %d!", result);
      return result;
    }

    // Read threshold registers (0x62-0x65).
    uint8_t threshBuf[4];
    result = readRegisters(M_REG_TH_HIGH_LSB, threshBuf, 4);
    if (result < 0) {
      LOG_ERR("Failed to read thresholds: %d!", result);
      return result;
    }

    uint16_t thHigh { static_cast<uint16_t>(threshBuf[0] | (threshBuf[1] << 8)) };
    uint16_t thLow { static_cast<uint16_t>(threshBuf[2] | (threshBuf[3] << 8)) };

    LOG_INF("BH1749 INT regs: INT=0x%02X, PERS=0x%02X, TH_H=%u, TH_L=%u",
            intReg, persReg, thHigh, thLow);

    // Decode INTERRUPT register bits.
    bool intEn { (intReg & M_INT_ENABLE) != 0 };
    uint8_t intSrc { static_cast<uint8_t>((intReg >> 2) & 0x03) };
    bool latch { (intReg & M_INT_LATCH_NO) == 0 };  // 0 = latched, 1 = non-latched.

    const char* srcNames[] = { "RED", "GREEN", "BLUE", "??" };
    LOG_INF("  INT enable=%d, source=%s, latched=%d", intEn, srcNames[intSrc], latch);

    return OK;
  }

  int Bh1749Light::ReadInterruptStatus(uint8_t& status)
  {
    if (!m_ready) { return -ENODEV; }
    return readRegister(M_REG_INTERRUPT, status);
  }

  bool Bh1749Light::WaitForValid(uint32_t timeoutMs)
  {
    if (!m_ready) { return false; }

    constexpr uint32_t M_POLL_INTERVAL_MS { 10 };
    uint32_t elapsed { 0 };

    while (elapsed < timeoutMs) {
      uint8_t ctrl2 { };
      int result { readRegister(M_REG_MODE_CONTROL2, ctrl2) };
      if (result < 0) {
        LOG_ERR("Failed to read MODE_CONTROL2: %d!", result);
        return false;
      }

      if (ctrl2 & M_VALID_MASK) {
        LOG_DBG("Valid data ready after %u ms.", elapsed);
        return true;
      }

      k_msleep(M_POLL_INTERVAL_MS);
      elapsed += M_POLL_INTERVAL_MS;
    }

    LOG_WRN("Timeout waiting for valid data (%u ms).", timeoutMs);
    return false;
  }

} // namespace fridge
```
